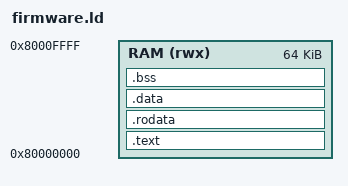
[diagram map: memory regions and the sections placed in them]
/* Bare-metal image for the FPGA ports: everything lives in the on-chip RAM
   that FpgaSoc maps at 0x80000000. RAM_SIZE must match RAM_WORDS * 4. */
OUTPUT_ARCH(riscv)
ENTRY(_start)

MEMORY {
    RAM (rwx) : ORIGIN = 0x80000000, LENGTH = 64K
}

SECTIONS {
    .text : {
        KEEP(*(.text.init))
        *(.text .text.*)
    } > RAM

    .rodata : {
        *(.rodata .rodata.*)
    } > RAM

    .data : {
        *(.data .data.*)
        *(.sdata .sdata.*)
    } > RAM

    .bss (NOLOAD) : {
        _bss_start = .;
        *(.bss .bss.*)
        *(.sbss .sbss.*)
        *(COMMON)
        _bss_end = .;
    } > RAM

    . = ALIGN(16);
    _stack_top = ORIGIN(RAM) + LENGTH(RAM);

    /DISCARD/ : { *(.comment) *(.note*) *(.eh_frame*) }
}
